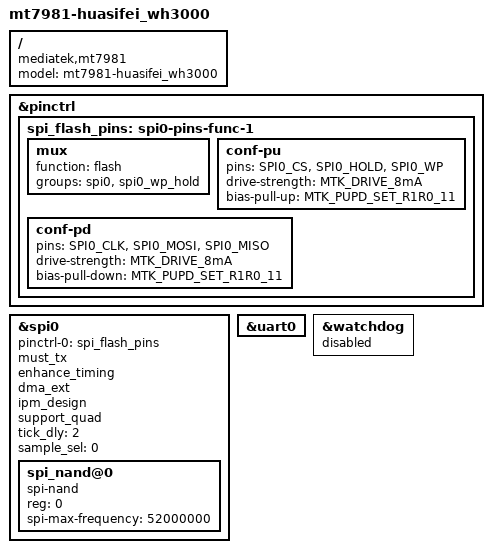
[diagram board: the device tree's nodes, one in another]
// SPDX-License-Identifier: GPL-2.0

/dts-v1/;
#include "mt7981-huasifei-wh3000.dtsi"

/ {
	model = "mt7981-huasifei_wh3000";
	compatible = "mediatek,mt7981", "mediatek,mt7981-rfb";
};

&pinctrl {
	spi_flash_pins: spi0-pins-func-1 {
		mux {
			function = "flash";
			groups = "spi0", "spi0_wp_hold";
		};

		conf-pu {
			pins = "SPI0_CS", "SPI0_HOLD", "SPI0_WP";
			drive-strength = <MTK_DRIVE_8mA>;
			bias-pull-up = <MTK_PUPD_SET_R1R0_11>;
		};

		conf-pd {
			pins = "SPI0_CLK", "SPI0_MOSI", "SPI0_MISO";
			drive-strength = <MTK_DRIVE_8mA>;
			bias-pull-down = <MTK_PUPD_SET_R1R0_11>;
		};
	};
};

&spi0 {
	#address-cells = <1>;
	#size-cells = <0>;
	pinctrl-names = "default";
	pinctrl-0 = <&spi_flash_pins>;
	status = "okay";
	must_tx;
	enhance_timing;
	dma_ext;
	ipm_design;
	support_quad;
	tick_dly = <2>;
	sample_sel = <0>;

	spi_nand@0 {
		compatible = "spi-nand";
		reg = <0>;
		spi-max-frequency = <52000000>;
	};
};

&uart0 {
	status = "okay";
};

&watchdog {
	status = "disabled";
};
